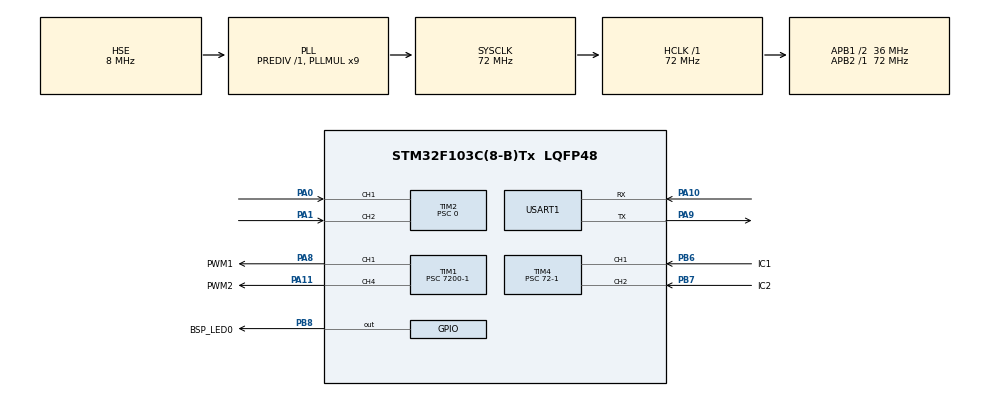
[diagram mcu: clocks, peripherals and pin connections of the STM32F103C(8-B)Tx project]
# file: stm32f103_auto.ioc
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Mcu.Family=STM32F1
Mcu.Name=STM32F103C(8-B)Tx
Mcu.Package=LQFP48
NVIC.PriorityGroup=NVIC_PRIORITYGROUP_4
NVIC.TIM2_IRQn=true\:0\:0\:false\:false\:true\:true\:true
NVIC.TIM4_IRQn=true\:1\:0\:true\:false\:true\:true\:true
PA0-WKUP.GPIO_PuPd=GPIO_PULLDOWN
PA0-WKUP.Signal=S_TIM2_CH1_ETR
PA1.GPIO_PuPd=GPIO_PULLDOWN
PA1.Signal=S_TIM2_CH2
PA10.Mode=Asynchronous
PA10.Signal=USART1_RX
PA11.GPIO_Label=PWM2
PA11.GPIO_ModeDefaultPP=GPIO_MODE_AF_PP
PA11.GPIO_Speed=GPIO_SPEED_FREQ_HIGH
PA11.Signal=S_TIM1_CH4
PA13.Mode=Serial_Wire
PA13.Signal=SYS_JTMS-SWDIO
PA14.Mode=Serial_Wire
PA14.Signal=SYS_JTCK-SWCLK
PA8.GPIO_Label=PWM1
PA8.GPIO_ModeDefaultPP=GPIO_MODE_AF_PP
PA8.GPIO_Speed=GPIO_SPEED_FREQ_HIGH
PA8.Signal=S_TIM1_CH1
PA9.Mode=Asynchronous
PA9.Signal=USART1_TX
PB6.GPIO_Label=IC1
PB6.GPIO_PuPd=GPIO_PULLDOWN
PB6.Signal=S_TIM4_CH1
PB7.GPIO_Label=IC2
PB7.GPIO_PuPd=GPIO_PULLDOWN
PB7.Signal=S_TIM4_CH2
PB8.GPIO_Label=BSP_LED0
PB8.GPIO_ModeDefaultOutputPP=GPIO_MODE_OUTPUT_OD
PB8.GPIO_PuPd=GPIO_PULLUP
PB8.PinState=GPIO_PIN_SET
PB8.Signal=GPIO_Output
PD0-OSC_IN.Mode=HSE-External-Oscillator
PD0-OSC_IN.Signal=RCC_OSC_IN
PD1-OSC_OUT.Mode=HSE-External-Oscillator
PD1-OSC_OUT.Signal=RCC_OSC_OUT
ProjectManager.HeapSize=0x200
ProjectManager.StackSize=0x400
ProjectManager.TargetToolchain=MDK-ARM V5
RCC.AHBFreq_Value=72000000
RCC.APB1CLKDivider=RCC_HCLK_DIV2
RCC.APB1Freq_Value=36000000
RCC.APB1TimFreq_Value=72000000
RCC.APB2Freq_Value=72000000
RCC.APB2TimFreq_Value=72000000
RCC.HCLKFreq_Value=72000000
RCC.PLLMUL=RCC_PLL_MUL9
RCC.PLLSourceVirtual=RCC_PLLSOURCE_HSE
RCC.SYSCLKFreq_VALUE=72000000
RCC.SYSCLKSource=RCC_SYSCLKSOURCE_PLLCLK
RCC.USBFreq_Value=72000000
SH.S_TIM1_CH1.0=TIM1_CH1,PWM Generation1 CH1
SH.S_TIM1_CH4.0=TIM1_CH4,PWM Generation4 CH4
SH.S_TIM2_CH1_ETR.0=TIM2_CH1,Encoder_Interface
SH.S_TIM2_CH2.0=TIM2_CH2,Encoder_Interface
SH.S_TIM4_CH1.0=TIM4_CH1,Input_Capture1_from_TI1
SH.S_TIM4_CH2.0=TIM4_CH2,Input_Capture2_from_TI2
TIM1.AutoReloadPreload=TIM_AUTORELOAD_PRELOAD_ENABLE
TIM1.Channel-PWM\ Generation1\ CH1=TIM_CHANNEL_1
TIM1.Channel-PWM\ Generation4\ CH4=TIM_CHANNEL_4
TIM1.CounterMode=TIM_COUNTERMODE_DOWN
TIM1.OCFastMode_PWM-PWM\ Generation1\ CH1=TIM_OCFAST_ENABLE
TIM1.OCFastMode_PWM-PWM\ Generation4\ CH4=TIM_OCFAST_ENABLE
TIM1.Period=10000-1
TIM1.Prescaler=7200-1
TIM1.Pulse-PWM\ Generation1\ CH1=5000
TIM1.Pulse-PWM\ Generation4\ CH4=5000
TIM2.EncoderMode=TIM_ENCODERMODE_TI12
TIM2.IC1Filter=0
TIM2.IC1Prescaler=TIM_ICPSC_DIV1
TIM2.IC2Filter=0
TIM2.IC2Prescaler=TIM_ICPSC_DIV1
TIM2.Period=1600-1
TIM2.Prescaler=0
TIM4.Channel-Input_Capture1_from_TI1=TIM_CHANNEL_1
TIM4.Channel-Input_Capture2_from_TI2=TIM_CHANNEL_2
TIM4.ClockDivision=TIM_CLOCKDIVISION_DIV1
TIM4.ICPrescaler-Input_Capture1_from_TI1=TIM_ICPSC_DIV4
TIM4.ICPrescaler-Input_Capture2_from_TI2=TIM_ICPSC_DIV4
TIM4.Period=10000
TIM4.Prescaler=72-1
USART1.VirtualMode=VM_ASYNC
VP_TIM1_VS_ClockSourceINT.Mode=Internal
VP_TIM4_VS_ClockSourceINT.Mode=Internal
board=custom

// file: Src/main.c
/* USER CODE BEGIN Header */
/**
  ******************************************************************************
  * @file           : main.c
  * @brief          : Main program body
  ******************************************************************************
  * @attention
  *
  * <h2><center>&copy; Copyright (c) 2019 STMicroelectronics.
  * All rights reserved.</center></h2>
  *
  * This software component is licensed by ST under BSD 3-Clause license,
  * the "License"; You may not use this file except in compliance with the
  * License. You may obtain a copy of the License at:
  *                        opensource.org/licenses/BSD-3-Clause
  *
  ******************************************************************************
  */
/* USER CODE END Header */

#include "main.h"
#include "tim.h"
#include "usart.h"
#include "gpio.h"

/* USER CODE BEGIN Includes */
#include "stdio.h"
#include "../BSP/inc/pwm.h"
#include "../BSP/inc/encode.h"
/* USER CODE END Includes */

void SystemClock_Config(void);

int main(void)
{

  /* MCU Configuration--------------------------------------------------------*/

  /* Reset of all peripherals, Initializes the Flash interface and the Systick. */
  HAL_Init();

  /* Configure the system clock */
  SystemClock_Config();

  /* Initialize all configured peripherals */
  MX_GPIO_Init();
  MX_TIM1_Init();
  MX_USART1_UART_Init();
  MX_TIM4_Init();
  MX_TIM2_Init();
  /* USER CODE BEGIN 2 */
	HAL_TIM_Encoder_Start_IT(&htim2, TIM_CHANNEL_ALL);
	BSP_ENCODE_START();
	BSP_PWM_START(PWM1);
	BSP_PWM_START(PWM2);
	printf("pwm start!!\r\n");
  /* USER CODE END 2 */

  /* Infinite loop */
  while (1)
  {

    /* USER CODE BEGIN 3 */
		HAL_Delay(500);
		//HAL_GPIO_TogglePin(BSP_LED0_GPIO_Port, BSP_LED0_Pin);
		//printf("encode: %d\r\n",__HAL_TIM_GET_COUNTER(&htim2));
  }
  /* USER CODE END 3 */
}

void SystemClock_Config(void)
{
  RCC_OscInitTypeDef RCC_OscInitStruct = {0};
  RCC_ClkInitTypeDef RCC_ClkInitStruct = {0};

  /** Initializes the CPU, AHB and APB busses clocks
  */
  RCC_OscInitStruct.OscillatorType = RCC_OSCILLATORTYPE_HSE;
  RCC_OscInitStruct.HSEState = RCC_HSE_ON;
  RCC_OscInitStruct.HSEPredivValue = RCC_HSE_PREDIV_DIV1;
  RCC_OscInitStruct.HSIState = RCC_HSI_ON;
  RCC_OscInitStruct.PLL.PLLState = RCC_PLL_ON;
  RCC_OscInitStruct.PLL.PLLSource = RCC_PLLSOURCE_HSE;
  RCC_OscInitStruct.PLL.PLLMUL = RCC_PLL_MUL9;
  if (HAL_RCC_OscConfig(&RCC_OscInitStruct) != HAL_OK)
  {
    Error_Handler();
  }
  /** Initializes the CPU, AHB and APB busses clocks
  */
  RCC_ClkInitStruct.ClockType = RCC_CLOCKTYPE_HCLK|RCC_CLOCKTYPE_SYSCLK
                              |RCC_CLOCKTYPE_PCLK1|RCC_CLOCKTYPE_PCLK2;
  RCC_ClkInitStruct.SYSCLKSource = RCC_SYSCLKSOURCE_PLLCLK;
  RCC_ClkInitStruct.AHBCLKDivider = RCC_SYSCLK_DIV1;
  RCC_ClkInitStruct.APB1CLKDivider = RCC_HCLK_DIV2;
  RCC_ClkInitStruct.APB2CLKDivider = RCC_HCLK_DIV1;

  if (HAL_RCC_ClockConfig(&RCC_ClkInitStruct, FLASH_LATENCY_2) != HAL_OK)
  {
    Error_Handler();
  }
}

void Error_Handler(void)
{
}

/************************ (C) COPYRIGHT STMicroelectronics *****END OF FILE****/
